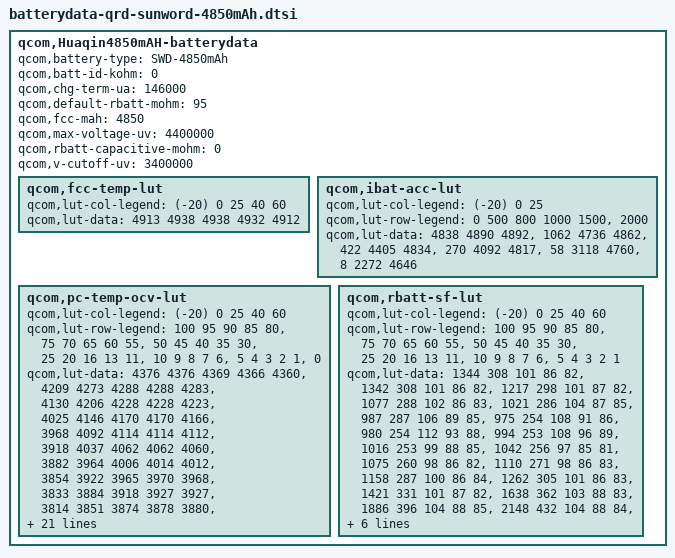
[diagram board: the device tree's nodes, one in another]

qcom,Huaqin4850mAH-batterydata {
	qcom,battery-type = "SWD-4850mAh";
	qcom,batt-id-kohm = <0>;
	qcom,chg-term-ua = <146000>;
	qcom,default-rbatt-mohm = <95>;
	qcom,fcc-mah = <4850>;
	qcom,max-voltage-uv = <4400000>;
	qcom,rbatt-capacitive-mohm = <0>;
	qcom,v-cutoff-uv = <3400000>;

	qcom,fcc-temp-lut {
		qcom,lut-col-legend = <(-20) 0 25 40 60>;
		qcom,lut-data = <4913 4938 4938 4932 4912>;
	};

	qcom,ibat-acc-lut {
		qcom,lut-col-legend = <(-20) 0 25>;
		qcom,lut-row-legend = <0 500 800 1000 1500>,
					<2000>;
		qcom,lut-data = <4838 4890 4892>,
				<1062 4736 4862>,
				<422 4405 4834>,
				<270 4092 4817>,
				<58 3118 4760>,
				<8 2272 4646>;
	};

	qcom,pc-temp-ocv-lut {
		qcom,lut-col-legend = <(-20) 0 25 40 60>;
		qcom,lut-row-legend = <100 95 90 85 80>,
					<75 70 65 60 55>,
					<50 45 40 35 30>,
					<25 20 16 13 11>,
					<10 9 8 7 6>,
					<5 4 3 2 1>,
					<0>;
		qcom,lut-data = <4376 4376 4369 4366 4360>,
				<4209 4273 4288 4288 4283>,
				<4130 4206 4228 4228 4223>,
				<4025 4146 4170 4170 4166>,
				<3968 4092 4114 4114 4112>,
				<3918 4037 4062 4062 4060>,
				<3882 3964 4006 4014 4012>,
				<3854 3922 3965 3970 3968>,
				<3833 3884 3918 3927 3927>,
				<3814 3851 3874 3878 3880>,
				<3796 3824 3842 3844 3842>,
				<3778 3801 3818 3818 3817>,
				<3761 3786 3798 3798 3798>,
				<3744 3772 3782 3782 3780>,
				<3726 3759 3768 3766 3763>,
				<3705 3744 3755 3750 3738>,
				<3684 3726 3738 3731 3717>,
				<3660 3710 3720 3712 3700>,
				<3640 3698 3702 3694 3682>,
				<3626 3690 3690 3683 3670>,
				<3618 3685 3686 3680 3668>,
				<3607 3678 3684 3678 3668>,
				<3594 3672 3682 3676 3664>,
				<3580 3663 3679 3674 3662>,
				<3563 3650 3674 3668 3657>,
				<3542 3630 3664 3657 3644>,
				<3516 3601 3634 3627 3610>,
				<3481 3559 3583 3576 3559>,
				<3432 3497 3514 3506 3490>,
				<3356 3403 3410 3406 3390>,
				<3200 3200 3200 3200 3200>;
	};

	qcom,rbatt-sf-lut {
		qcom,lut-col-legend = <(-20) 0 25 40 60>;
		qcom,lut-row-legend = <100 95 90 85 80>,
					<75 70 65 60 55>,
					<50 45 40 35 30>,
					<25 20 16 13 11>,
					<10 9 8 7 6>,
					<5 4 3 2 1>;
		qcom,lut-data = <1344 308 101 86 82>,
				<1342 308 101 86 82>,
				<1217 298 101 87 82>,
				<1077 288 102 86 83>,
				<1021 286 104 87 85>,
				<987 287 106 89 85>,
				<975 254 108 91 86>,
				<980 254 112 93 88>,
				<994 253 108 96 89>,
				<1016 253 99 88 85>,
				<1042 256 97 85 81>,
				<1075 260 98 86 82>,
				<1110 271 98 86 83>,
				<1158 287 100 86 84>,
				<1262 305 101 86 83>,
				<1421 331 101 87 82>,
				<1638 362 103 88 83>,
				<1886 396 104 88 85>,
				<2148 432 104 88 84>,
				<2294 446 104 87 83>,
				<2473 464 105 88 84>,
				<2679 485 107 88 86>,
				<2932 512 109 90 87>,
				<3238 542 112 92 90>,
				<3590 576 115 94 92>,
				<4060 623 119 96 92>,
				<4677 676 116 92 87>,
				<5500 755 115 90 87>,
				<6668 890 121 93 88>,
				<8456 1169 132 96 88>;
	};
};
/* TEST_DB_ID=TEST_ID_NOT_SET */
